AUTOSAR XML (schema 4-0-3)
standard types defined: Boolean, UInt8
package /AUTOSAR_Platform/DataConstrs
  range DC_Boolean: raw 0..1
package /DataTypes/Units
  unit NoUnit1: display-name=NoUnit, factor-si-to-unit=1, offset-si-to-unit=0
package /PATAC/MSM/ComponentTypes
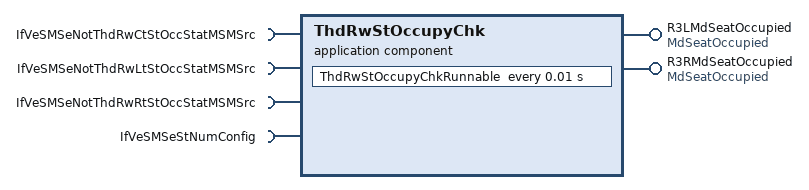
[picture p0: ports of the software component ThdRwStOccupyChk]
  application sw component type ThdRwStOccupyChk
    provide port R3LMdSeatOccupied: nonqueued-sender-com-spec{data-element=MdSeatOccupied/Val, init-value=0}, provided-interface=MdSeatOccupied
    provide port R3RMdSeatOccupied: nonqueued-sender-com-spec{data-element=MdSeatOccupied/Val, init-value=0}, provided-interface=MdSeatOccupied
    4 x require port:
      IfVeSMSeNotThdRwCtStOccStatMSMSrc: nonqueued-receiver-com-spec{data-element=IfVeSMSeNotThdRwCtStOccStatMSMSrc/Val, filter=data-filter-type=ALWAYS, init-value=0}, required-interface=IfVeSMSeNotThdRwCtStOccStatMSMSrc
      IfVeSMSeNotThdRwLtStOccStatMSMSrc: nonqueued-receiver-com-spec{data-element=IfVeSMSeNotThdRwLtStOccStatMSMSrc/Val, filter=data-filter-type=ALWAYS, init-value=0}, required-interface=IfVeSMSeNotThdRwLtStOccStatMSMSrc
      IfVeSMSeNotThdRwRtStOccStatMSMSrc: nonqueued-receiver-com-spec{data-element=IfVeSMSeNotThdRwRtStOccStatMSMSrc/Val, filter=data-filter-type=ALWAYS, init-value=0}, required-interface=IfVeSMSeNotThdRwRtStOccStatMSMSrc
      IfVeSMSeStNumConfig: nonqueued-receiver-com-spec{data-element=IfVeSMSeStNumConfig/Val, filter=data-filter-type=ALWAYS, init-value=0}, required-interface=IfVeSMSeStNumConfig
    behavior ThdRwStOccupyChk_InternalBehavior
      timing event TMT_ThdRwStOccupyChkRunnable: start-on-event=ThdRwStOccupyChkRunnable, period=0.01
      runnable ThdRwStOccupyChkRunnable
        data-receive-point-by-arguments:
          4 x access:
            REC_IfVeSMSeNotThdRwCtStOccStatMSMSrc_Val: accessed-variable=IfVeSMSeNotThdRwCtStOccStatMSMSrc.Val
            REC_IfVeSMSeNotThdRwLtStOccStatMSMSrc_Val: accessed-variable=IfVeSMSeNotThdRwLtStOccStatMSMSrc.Val
            REC_IfVeSMSeNotThdRwRtStOccStatMSMSrc_Val: accessed-variable=IfVeSMSeNotThdRwRtStOccStatMSMSrc.Val
            REC_IfVeSMSeStNumConfig_Val: accessed-variable=IfVeSMSeStNumConfig.Val
        data-send-points:
          access SEND_R3LMdSeatOccupied_Val: accessed-variable=R3LMdSeatOccupied.Val
          access SEND_R3RMdSeatOccupied_Val: accessed-variable=R3RMdSeatOccupied.Val
  swc implementation ThdRwStOccupyChk_Implementation: behavior=ThdRwStOccupyChk_InternalBehavior
    code-descriptors:
      code Default: artifact-descriptors=autosar-engineering-object={short-label=Default, category=SWSRC}
package /PATAC/MSM/DataTypes/ImplementationDataTypes
  impl type IfVeSMSeStNumConfig: category=VALUE, base-type=UInt8, sw-calibration-access=READ-ONLY, compu {0=SeatNum4Config, 1=SeatNum6Config, 2=SeatNum7Config, 3=SeatNum4PConfig}, type-emitter=RTE
package /PATAC/MSM/ModeAdjust/DataType
  impl type SeatOccupiedSts1: category=VALUE, base-type=UInt8, sw-calibration-access=READ-ONLY, compu {0=SeatOccupiedSts_Unknown, 1=SeatOccupiedSts_Empty, 2=SeatOccupiedSts_Occupied, 3=SeatOccupiedSts_DataNotAvailable}, type-emitter=RTE
package /PATAC/MSM/ModeAdjust/Interfaces
  sender receiver interface IfVeSMSeNotThdRwCtStOccStatMSMSrc: invalidation-policy{data-element=IfVeSMSeNotThdRwCtStOccStatMSMSrc/Val, handle-invalid=DONT-INVALIDATE}
    data Val: type=SeatOccupiedSts1
  sender receiver interface IfVeSMSeNotThdRwLtStOccStatMSMSrc: invalidation-policy{data-element=IfVeSMSeNotThdRwLtStOccStatMSMSrc/Val, handle-invalid=DONT-INVALIDATE}
    data Val: type=SeatOccupiedSts1
  sender receiver interface IfVeSMSeNotThdRwRtStOccStatMSMSrc: invalidation-policy{data-element=IfVeSMSeNotThdRwRtStOccStatMSMSrc/Val, handle-invalid=DONT-INVALIDATE}
    data Val: type=SeatOccupiedSts1
package /PATAC/MSM/ModeAdjust/PortInterface
  sender receiver interface IfVeSMSeStNumConfig: invalidation-policy{data-element=IfVeSMSeStNumConfig/Val, handle-invalid=DONT-INVALIDATE}
    data Val: type=IfVeSMSeStNumConfig
  sender receiver interface MdSeatOccupied: invalidation-policy{data-element=MdSeatOccupied/Val, handle-invalid=DONT-INVALIDATE}
    data Val: type=Boolean
